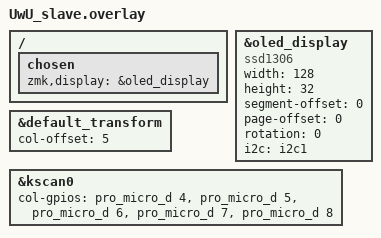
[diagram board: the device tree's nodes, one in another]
/*
 * Copyright (c) 2025 Ellie Ernst
 *
 * SPDX-License-Identifier: MIT
 */

#include "UwU.dtsi"

/ {
    chosen {
        zmk,display = &oled_display;
    };
};

&oled_display {
    compatible = "ssd1306";
    width = <128>;
    height = <32>;
    segment-offset = <0>;
    page-offset = <0>;
    rotation = <0>;  // Adjust based on your mounting (0, 90, 180, 270)
    i2c = <&i2c1>;   // Change based on your board's I2C configuration
};

&default_transform {
	col-offset = <5>;
};

&kscan0 {
	col-gpios
		= <&pro_micro_d 4 GPIO_ACTIVE_HIGH>
		, <&pro_micro_d 5 GPIO_ACTIVE_HIGH>
		, <&pro_micro_d 6 GPIO_ACTIVE_HIGH>
		, <&pro_micro_d 7 GPIO_ACTIVE_HIGH>
		, <&pro_micro_d 8 GPIO_ACTIVE_HIGH>
		;
};
